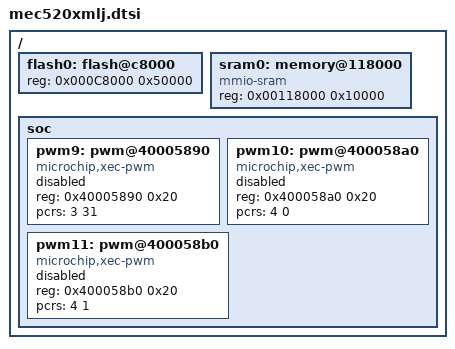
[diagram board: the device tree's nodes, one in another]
/*
 * Copyright (c) 2023 Silicom Connectivity Solutions, Ltd.
 *
 * SPDX-License-Identifier: Apache-2.0
 */

#include <arm/armv7-m.dtsi>

#include <zephyr/dt-bindings/i2c/i2c.h>
#include <zephyr/dt-bindings/gpio/gpio.h>
#include <zephyr/dt-bindings/clock/mchp_xec_pcr.h>
#include <zephyr/dt-bindings/interrupt-controller/mchp-xec-ecia.h>

#include "mec172x.dtsi"
#include "mec172x/mec172x-vw-routing.dtsi"
#include "mec172x/mec172xnsz-pinctrl.dtsi"
#include "mec172x/mec172xnlj-pinctrl.dtsi"

/ {

	flash0: flash@c8000 {
		reg = <0x000C8000 0x50000>;
	};

	sram0: memory@118000 {
		compatible = "mmio-sram";
		reg = <0x00118000 0x10000>;
	};

	soc {
		pwm9: pwm@40005890 {
			compatible = "microchip,xec-pwm";
			reg = <0x40005890 0x20>;
			pcrs = <3 31>;
			status = "disabled";
			#pwm-cells = <3>;
		};

		pwm10: pwm@400058a0 {
			compatible = "microchip,xec-pwm";
			reg = <0x400058a0 0x20>;
			pcrs = <4 0>;
			status = "disabled";
			#pwm-cells = <3>;
		};

		pwm11: pwm@400058b0 {
			compatible = "microchip,xec-pwm";
			reg = <0x400058b0 0x20>;
			pcrs = <4 1>;
			status = "disabled";
			#pwm-cells = <3>;
		};

		/* TODO PowerGuard */
		/* TODO ENVMON */
		/* TODO PROCHOT_IO? */
		/* TODO No SPI Target */
		/* TODO No internal SPI port */
		/* TODO No EEPROM */
		/* TODO No keyscan */
		/* TODO No Vref-2 ADC pin */
		/* TODO No Analog comparators */
	};
};
